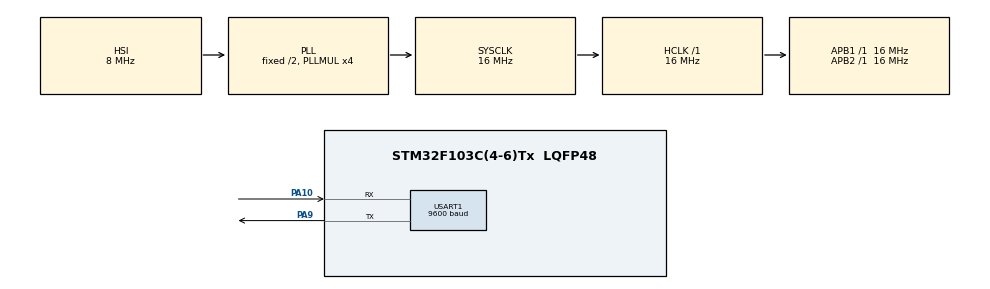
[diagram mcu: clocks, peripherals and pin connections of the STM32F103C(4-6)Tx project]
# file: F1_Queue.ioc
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FREERTOS.Tasks01=defaultTask,0,128,StartDefaultTask,Default,NULL,Dynamic,NULL,NULL
Mcu.Family=STM32F1
Mcu.Name=STM32F103C(4-6)Tx
Mcu.Package=LQFP48
NVIC.PriorityGroup=NVIC_PRIORITYGROUP_4
NVIC.TIM1_UP_IRQn=true\:15\:0\:false\:false\:true\:false\:false\:true\:true
NVIC.TimeBase=TIM1_UP_IRQn
NVIC.TimeBaseIP=TIM1
PA10.Mode=Asynchronous
PA10.Signal=USART1_RX
PA9.Mode=Asynchronous
PA9.Signal=USART1_TX
ProjectManager.HeapSize=0x200
ProjectManager.StackSize=0x400
ProjectManager.TargetToolchain=STM32CubeIDE
RCC.AHBFreq_Value=16000000
RCC.APB1Freq_Value=16000000
RCC.APB1TimFreq_Value=16000000
RCC.APB2Freq_Value=16000000
RCC.APB2TimFreq_Value=16000000
RCC.HCLKFreq_Value=16000000
RCC.PLLMUL=RCC_PLL_MUL4
RCC.SYSCLKFreq_VALUE=16000000
RCC.SYSCLKSource=RCC_SYSCLKSOURCE_PLLCLK
RCC.USBFreq_Value=16000000
USART1.BaudRate=9600
USART1.VirtualMode=VM_ASYNC
VP_FREERTOS_VS_CMSIS_V1.Mode=CMSIS_V1
VP_SYS_VS_ND.Mode=No_Debug
VP_SYS_VS_tim1.Mode=TIM1
board=custom

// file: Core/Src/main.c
/* USER CODE BEGIN Header */
/**
  ******************************************************************************
  * @file           : main.c
  * @brief          : Main program body
  ******************************************************************************
  * @attention
  *
  * Copyright (c) 2025 STMicroelectronics.
  * All rights reserved.
  *
  * This software is licensed under terms that can be found in the LICENSE file
  * in the root directory of this software component.
  * If no LICENSE file comes with this software, it is provided AS-IS.
  *
  ******************************************************************************
  */
/* USER CODE END Header */
#include "main.h"

/* USER CODE BEGIN Includes */
#include "FreeRTOS.h"
#include "task.h"
#include "timers.h"
#include "queue.h"
#include "semphr.h"
#include "event_groups.h"

#include "string.h"
#include "stdio.h"
/* USER CODE END Includes */

UART_HandleTypeDef huart1;

void SystemClock_Config(void);
static void MX_GPIO_Init(void);
static void MX_USART1_UART_Init(void);

/* USER CODE BEGIN 0 */
/***QUEUEHandler */
xQueueHandle St_Queue_Handler;

//Task Handler
xTaskHandle Sender1_Task_Handler;
xTaskHandle Sender2_Task_Handler;
xTaskHandle Receiver_Task_Handler;

//Task functions
void Sender1_Task(void *argument);
void Sender2_Task(void *argument);
void Receiver_Task(void *argument);
//Structure Definition
typedef struct{
	char *str;
	int counter;
	uint16_t large_value;
} my_struct;

int indx1=0;
int indx2=0;

/* USER CODE END 0 */

int main(void)
{

  /* MCU Configuration--------------------------------------------------------*/

  /* Reset of all peripherals, Initializes the Flash interface and the Systick. */
  HAL_Init();

  /* Configure the system clock */
  SystemClock_Config();

  /* Initialize all configured peripherals */
  MX_GPIO_Init();
  MX_USART1_UART_Init();
  /* USER CODE BEGIN 2 */

  //se crea la Queue
  St_Queue_Handler = xQueueCreate(2,sizeof(my_struct)); /*puede guardar dos elementos del tamaño
  de la estructura */
  char *prueba= "Hola mundo\r\n";
  	  HAL_UART_Transmit(&huart1,(uint8_t *)prueba,strlen(prueba),HAL_MAX_DELAY);

  if(St_Queue_Handler==0){
	  char *str= "Unable to create Structure Queue\r\n";
	  HAL_UART_Transmit(&huart1,(uint8_t *)str,strlen(str),HAL_MAX_DELAY);
  }else{
	  char *str= "Structure created\r\n";
	  HAL_UART_Transmit(&huart1,(uint8_t *)str,strlen(str),HAL_MAX_DELAY);
  }

  /**Se crea la tarea***/
  //función de la tarea, nombre de la tarea,stack depth, parámetro, prioridad y handler
  xTaskCreate(Sender1_Task,"Sender1",128,NULL,2,&Sender1_Task_Handler);
  xTaskCreate(Sender2_Task,"Sender2",128,NULL,2,&Sender2_Task_Handler);
  xTaskCreate(Receiver_Task,"Receiver",128,NULL,1,&Receiver_Task_Handler);

  //scheduler
  vTaskStartScheduler();

  /* USER CODE END 2 */

  /* Create the thread(s) */
  /* definition and creation of defaultTask */

  /* Start scheduler */

  /* We should never get here as control is now taken by the scheduler */

  /* Infinite loop */
  while (1)
  {

  }
}

void SystemClock_Config(void)
{
  RCC_OscInitTypeDef RCC_OscInitStruct = {0};
  RCC_ClkInitTypeDef RCC_ClkInitStruct = {0};

  /** Initializes the RCC Oscillators according to the specified parameters
  * in the RCC_OscInitTypeDef structure.
  */
  RCC_OscInitStruct.OscillatorType = RCC_OSCILLATORTYPE_HSI;
  RCC_OscInitStruct.HSIState = RCC_HSI_ON;
  RCC_OscInitStruct.HSICalibrationValue = RCC_HSICALIBRATION_DEFAULT;
  RCC_OscInitStruct.PLL.PLLState = RCC_PLL_ON;
  RCC_OscInitStruct.PLL.PLLSource = RCC_PLLSOURCE_HSI_DIV2;
  RCC_OscInitStruct.PLL.PLLMUL = RCC_PLL_MUL4;
  if (HAL_RCC_OscConfig(&RCC_OscInitStruct) != HAL_OK)
  {
    Error_Handler();
  }

  /** Initializes the CPU, AHB and APB buses clocks
  */
  RCC_ClkInitStruct.ClockType = RCC_CLOCKTYPE_HCLK|RCC_CLOCKTYPE_SYSCLK
                              |RCC_CLOCKTYPE_PCLK1|RCC_CLOCKTYPE_PCLK2;
  RCC_ClkInitStruct.SYSCLKSource = RCC_SYSCLKSOURCE_PLLCLK;
  RCC_ClkInitStruct.AHBCLKDivider = RCC_SYSCLK_DIV1;
  RCC_ClkInitStruct.APB1CLKDivider = RCC_HCLK_DIV1;
  RCC_ClkInitStruct.APB2CLKDivider = RCC_HCLK_DIV1;

  if (HAL_RCC_ClockConfig(&RCC_ClkInitStruct, FLASH_LATENCY_0) != HAL_OK)
  {
    Error_Handler();
  }
}

static void MX_USART1_UART_Init(void)
{

//
  huart1.Instance = USART1;
  huart1.Init.BaudRate = 9600;
  huart1.Init.WordLength = UART_WORDLENGTH_8B;
  huart1.Init.StopBits = UART_STOPBITS_1;
  huart1.Init.Parity = UART_PARITY_NONE;
  huart1.Init.Mode = UART_MODE_TX_RX;
  huart1.Init.HwFlowCtl = UART_HWCONTROL_NONE;
  huart1.Init.OverSampling = UART_OVERSAMPLING_16;
  if (HAL_UART_Init(&huart1) != HAL_OK)
  {
    Error_Handler();
  }

}

static void MX_GPIO_Init(void)
{

  /* GPIO Ports Clock Enable */
  __HAL_RCC_GPIOA_CLK_ENABLE();

}

/* USER CODE BEGIN 4 */

void Sender1_Task(void *argument){
	my_struct *ptrtostruct;
	uint32_t TickDelay=pdMS_TO_TICKS(2000);
	while(1){
		char *str= "Entered SENDER1_Task\r\n";
		HAL_UART_Transmit(&huart1,(uint8_t*)str,strlen(str),HAL_MAX_DELAY);

		//Allocate memory to the pointer
		ptrtostruct = pvPortMalloc(sizeof(my_struct));
//
		//cargar los datos a la estructura
		ptrtostruct->counter=1+indx1;
		ptrtostruct->large_value=1000+indx1*100;
		ptrtostruct->str="Hello from sender1\r\n";

		//enviar a la queue
		if(xQueueSend(St_Queue_Handler,&ptrtostruct,portMAX_DELAY)==pdPASS){
			char *str2= "Enviado a la queue con éxito, terminando Sender1_Task\r\n";
			HAL_UART_Transmit(&huart1,(uint8_t*)str2,strlen(str2),HAL_MAX_DELAY);
		}
		indx1=indx1+1;
		vTaskDelay(TickDelay);
	}
}

void Sender2_Task(void *argument){
	my_struct *ptrtostruct;
	uint32_t TickDelay=pdMS_TO_TICKS(2000);
	while(1){
		char *str= "Entered SENDER2_Task\r\n";
		HAL_UART_Transmit(&huart1,(uint8_t*)str,strlen(str),HAL_MAX_DELAY);

		//Allocate memory to the pointer
		ptrtostruct = pvPortMalloc(sizeof(my_struct));

		//cargar los datos a la estructura
		ptrtostruct->counter=1+indx2;
		ptrtostruct->large_value=2000+indx2*200;
		ptrtostruct->str="Hello from sender2\r\n";

		//enviar a la queue
		if(xQueueSend(St_Queue_Handler,&ptrtostruct,portMAX_DELAY)==pdPASS){
			char *str2= "Enviado a la queue con éxito, terminando Sender2_Task\r\n";
			HAL_UART_Transmit(&huart1,(uint8_t*)str2,strlen(str2),HAL_MAX_DELAY);
		}
		indx2=indx2+1;
		vTaskDelay(TickDelay);
	}
}
void Receiver_Task(void *argument){
	my_struct *Rptrtostruct;
	uint32_t TickDelay=pdMS_TO_TICKS(3000);
	char *ptr;

	while(1){
		char *str= "Entered Receiver_Task\r\n";
		HAL_UART_Transmit(&huart1,(uint8_t*)str,strlen(str),HAL_MAX_DELAY);

		//recibir datos de la queue
		if(xQueueReceive(St_Queue_Handler,&Rptrtostruct,portMAX_DELAY)==pdPASS){
			ptr=pvPortMalloc(100*sizeof(char));
			sprintf(ptr,"Received from QUEUE: \r\n Counter %d\r\n Large value= %u\r\n String %s \r\n\r\n\r\n",Rptrtostruct->counter,Rptrtostruct->large_value,Rptrtostruct->str);
			HAL_UART_Transmit(&huart1,(uint8_t*)ptr,strlen(ptr),HAL_MAX_DELAY);
			vPortFree(ptr); //se libera la memoria del pointer
		}
		//se debe liberar la memoria de los senders
		vPortFree(Rptrtostruct);
		vTaskDelay(TickDelay);
	}
}

void HAL_TIM_PeriodElapsedCallback(TIM_HandleTypeDef *htim)
{
  if (htim->Instance == TIM1)
  {
    HAL_IncTick();
  }
}

void Error_Handler(void)
{
  __disable_irq();
  while (1)
  {
  }
}
